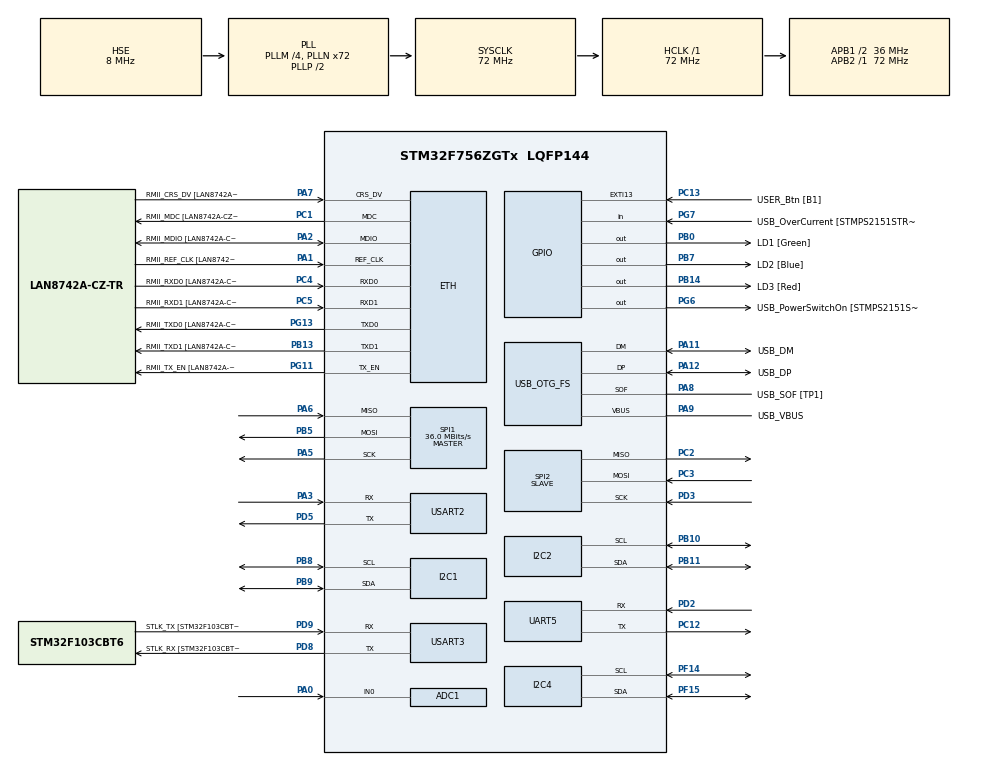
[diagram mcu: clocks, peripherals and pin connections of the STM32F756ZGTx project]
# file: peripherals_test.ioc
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ADC1.Channel-0\#ChannelRegularConversion=ADC_CHANNEL_0
ADC1.NbrOfConversionFlag=1
ADC1.Rank-0\#ChannelRegularConversion=1
ADC1.SamplingTime-0\#ChannelRegularConversion=ADC_SAMPLETIME_3CYCLES
ADC1.master=1
Dma.ADC1.8.Direction=DMA_PERIPH_TO_MEMORY
Dma.ADC1.8.FIFOMode=DMA_FIFOMODE_DISABLE
Dma.ADC1.8.Instance=DMA2_Stream4
Dma.ADC1.8.MemDataAlignment=DMA_MDATAALIGN_HALFWORD
Dma.ADC1.8.MemInc=DMA_MINC_ENABLE
Dma.ADC1.8.Mode=DMA_CIRCULAR
Dma.ADC1.8.PeriphDataAlignment=DMA_PDATAALIGN_HALFWORD
Dma.ADC1.8.PeriphInc=DMA_PINC_DISABLE
Dma.ADC1.8.Priority=DMA_PRIORITY_LOW
Dma.Request0=USART2_RX
Dma.Request1=USART2_TX
Dma.Request2=UART5_RX
Dma.Request3=UART5_TX
Dma.Request4=SPI1_RX
Dma.Request5=SPI1_TX
Dma.Request6=SPI2_RX
Dma.Request7=SPI2_TX
Dma.Request8=ADC1
Dma.SPI1_RX.4.Direction=DMA_PERIPH_TO_MEMORY
Dma.SPI1_RX.4.FIFOMode=DMA_FIFOMODE_ENABLE
Dma.SPI1_RX.4.FIFOThreshold=DMA_FIFO_THRESHOLD_FULL
Dma.SPI1_RX.4.Instance=DMA2_Stream0
Dma.SPI1_RX.4.MemBurst=DMA_MBURST_SINGLE
Dma.SPI1_RX.4.MemDataAlignment=DMA_MDATAALIGN_BYTE
Dma.SPI1_RX.4.MemInc=DMA_MINC_ENABLE
Dma.SPI1_RX.4.Mode=DMA_NORMAL
Dma.SPI1_RX.4.PeriphBurst=DMA_PBURST_SINGLE
Dma.SPI1_RX.4.PeriphDataAlignment=DMA_PDATAALIGN_BYTE
Dma.SPI1_RX.4.PeriphInc=DMA_PINC_DISABLE
Dma.SPI1_RX.4.Priority=DMA_PRIORITY_HIGH
Dma.SPI1_TX.5.Direction=DMA_MEMORY_TO_PERIPH
Dma.SPI1_TX.5.FIFOMode=DMA_FIFOMODE_ENABLE
Dma.SPI1_TX.5.FIFOThreshold=DMA_FIFO_THRESHOLD_FULL
Dma.SPI1_TX.5.Instance=DMA2_Stream3
Dma.SPI1_TX.5.MemBurst=DMA_MBURST_SINGLE
Dma.SPI1_TX.5.MemDataAlignment=DMA_MDATAALIGN_BYTE
Dma.SPI1_TX.5.MemInc=DMA_MINC_ENABLE
Dma.SPI1_TX.5.Mode=DMA_NORMAL
Dma.SPI1_TX.5.PeriphBurst=DMA_PBURST_SINGLE
Dma.SPI1_TX.5.PeriphDataAlignment=DMA_PDATAALIGN_BYTE
Dma.SPI1_TX.5.PeriphInc=DMA_PINC_DISABLE
Dma.SPI1_TX.5.Priority=DMA_PRIORITY_HIGH
Dma.SPI2_RX.6.Direction=DMA_PERIPH_TO_MEMORY
Dma.SPI2_RX.6.FIFOMode=DMA_FIFOMODE_ENABLE
Dma.SPI2_RX.6.FIFOThreshold=DMA_FIFO_THRESHOLD_FULL
Dma.SPI2_RX.6.Instance=DMA1_Stream3
Dma.SPI2_RX.6.MemBurst=DMA_MBURST_SINGLE
Dma.SPI2_RX.6.MemDataAlignment=DMA_MDATAALIGN_BYTE
Dma.SPI2_RX.6.MemInc=DMA_MINC_ENABLE
Dma.SPI2_RX.6.Mode=DMA_NORMAL
Dma.SPI2_RX.6.PeriphBurst=DMA_PBURST_SINGLE
Dma.SPI2_RX.6.PeriphDataAlignment=DMA_PDATAALIGN_BYTE
Dma.SPI2_RX.6.PeriphInc=DMA_PINC_DISABLE
Dma.SPI2_RX.6.Priority=DMA_PRIORITY_HIGH
Dma.SPI2_TX.7.Direction=DMA_MEMORY_TO_PERIPH
Dma.SPI2_TX.7.FIFOMode=DMA_FIFOMODE_ENABLE
Dma.SPI2_TX.7.FIFOThreshold=DMA_FIFO_THRESHOLD_FULL
Dma.SPI2_TX.7.Instance=DMA1_Stream4
Dma.SPI2_TX.7.MemBurst=DMA_MBURST_SINGLE
Dma.SPI2_TX.7.MemDataAlignment=DMA_MDATAALIGN_BYTE
Dma.SPI2_TX.7.MemInc=DMA_MINC_ENABLE
Dma.SPI2_TX.7.Mode=DMA_NORMAL
Dma.SPI2_TX.7.PeriphBurst=DMA_PBURST_SINGLE
Dma.SPI2_TX.7.PeriphDataAlignment=DMA_PDATAALIGN_BYTE
Dma.SPI2_TX.7.PeriphInc=DMA_PINC_DISABLE
Dma.SPI2_TX.7.Priority=DMA_PRIORITY_HIGH
Dma.UART5_RX.2.Direction=DMA_PERIPH_TO_MEMORY
Dma.UART5_RX.2.FIFOMode=DMA_FIFOMODE_DISABLE
Dma.UART5_RX.2.Instance=DMA1_Stream0
Dma.UART5_RX.2.MemDataAlignment=DMA_MDATAALIGN_BYTE
Dma.UART5_RX.2.MemInc=DMA_MINC_ENABLE
Dma.UART5_RX.2.Mode=DMA_NORMAL
Dma.UART5_RX.2.PeriphDataAlignment=DMA_PDATAALIGN_BYTE
Dma.UART5_RX.2.PeriphInc=DMA_PINC_DISABLE
Dma.UART5_RX.2.Priority=DMA_PRIORITY_LOW
Dma.UART5_TX.3.Direction=DMA_MEMORY_TO_PERIPH
Dma.UART5_TX.3.FIFOMode=DMA_FIFOMODE_DISABLE
Dma.UART5_TX.3.Instance=DMA1_Stream7
Dma.UART5_TX.3.MemDataAlignment=DMA_MDATAALIGN_BYTE
Dma.UART5_TX.3.MemInc=DMA_MINC_ENABLE
Dma.UART5_TX.3.Mode=DMA_NORMAL
Dma.UART5_TX.3.PeriphDataAlignment=DMA_PDATAALIGN_BYTE
Dma.UART5_TX.3.PeriphInc=DMA_PINC_DISABLE
Dma.UART5_TX.3.Priority=DMA_PRIORITY_LOW
Dma.USART2_RX.0.Direction=DMA_PERIPH_TO_MEMORY
Dma.USART2_RX.0.FIFOMode=DMA_FIFOMODE_DISABLE
Dma.USART2_RX.0.Instance=DMA1_Stream5
Dma.USART2_RX.0.MemDataAlignment=DMA_MDATAALIGN_BYTE
Dma.USART2_RX.0.MemInc=DMA_MINC_ENABLE
Dma.USART2_RX.0.Mode=DMA_NORMAL
Dma.USART2_RX.0.PeriphDataAlignment=DMA_PDATAALIGN_BYTE
Dma.USART2_RX.0.PeriphInc=DMA_PINC_DISABLE
Dma.USART2_RX.0.Priority=DMA_PRIORITY_LOW
Dma.USART2_TX.1.Direction=DMA_MEMORY_TO_PERIPH
Dma.USART2_TX.1.FIFOMode=DMA_FIFOMODE_DISABLE
Dma.USART2_TX.1.Instance=DMA1_Stream6
Dma.USART2_TX.1.MemDataAlignment=DMA_MDATAALIGN_BYTE
Dma.USART2_TX.1.MemInc=DMA_MINC_ENABLE
Dma.USART2_TX.1.Mode=DMA_NORMAL
Dma.USART2_TX.1.PeriphDataAlignment=DMA_PDATAALIGN_BYTE
Dma.USART2_TX.1.PeriphInc=DMA_PINC_DISABLE
Dma.USART2_TX.1.Priority=DMA_PRIORITY_LOW
ETH.MediaInterface=HAL_ETH_RMII_MODE
ETH.PHY_Name=LAN8742A_PHY_ADDRESS
ETH.PHY_Value=0
ETH.PhyAddress=0
I2C1.Timing=0x00808CD2
I2C2.Timing=0x00808CD2
I2C4.OwnAddress=0x02
I2C4.Timing=0x00808CD2
LWIP.BSP.number=1
LWIP.GATEWAY_ADDRESS=010.100.102.001
LWIP.IP_ADDRESS=010.100.102.100
LWIP.LWIP_DHCP=0
LWIP.LWIP_RAM_HEAP_POINTER=0x20048000
LWIP.NETMASK_ADDRESS=255.255.255.000
LWIP.Version=v2.1.2_Cube
LWIP0.BSP.STBoard=false
LWIP0.BSP.api=BSP_COMPONENT_DRIVER
LWIP0.BSP.component=LAN8742
LWIP0.BSP.instance=LAN8742
LWIP0.BSP.name=Driver_PHY
LWIP0.BSP.semaphore=S_LAN8742
LWIP0.BSP.solution=LAN8742
Mcu.Family=STM32F7
Mcu.Name=STM32F756ZGTx
Mcu.Package=LQFP144
NVIC.ADC_IRQn=true\:0\:0\:false\:false\:true\:true\:true\:true
NVIC.DMA1_Stream0_IRQn=true\:0\:0\:false\:false\:true\:false\:true\:true
NVIC.DMA1_Stream3_IRQn=true\:0\:0\:false\:false\:true\:false\:true\:true
NVIC.DMA1_Stream4_IRQn=true\:0\:0\:false\:false\:true\:false\:true\:true
NVIC.DMA1_Stream5_IRQn=true\:0\:0\:false\:false\:true\:false\:true\:true
NVIC.DMA1_Stream6_IRQn=true\:0\:0\:false\:false\:true\:false\:true\:true
NVIC.DMA1_Stream7_IRQn=true\:0\:0\:false\:false\:true\:false\:true\:true
NVIC.DMA2_Stream0_IRQn=true\:0\:0\:false\:false\:true\:false\:true\:true
NVIC.DMA2_Stream3_IRQn=true\:0\:0\:false\:false\:true\:false\:true\:true
NVIC.DMA2_Stream4_IRQn=true\:0\:0\:false\:false\:true\:false\:true\:true
NVIC.ETH_IRQn=true\:0\:0\:false\:false\:true\:true\:true\:true
NVIC.I2C2_EV_IRQn=true\:0\:0\:false\:false\:true\:true\:true\:true
NVIC.I2C4_EV_IRQn=true\:0\:0\:false\:false\:true\:true\:true\:true
NVIC.PriorityGroup=NVIC_PRIORITYGROUP_4
NVIC.SPI1_IRQn=true\:0\:0\:false\:false\:true\:true\:true\:true
NVIC.SPI2_IRQn=true\:0\:0\:false\:false\:true\:true\:true\:true
NVIC.TIM6_DAC_IRQn=true\:0\:0\:false\:false\:true\:true\:true\:true
NVIC.UART5_IRQn=true\:0\:0\:false\:false\:true\:true\:true\:true
NVIC.USART2_IRQn=true\:0\:0\:false\:false\:true\:true\:true\:true
PA0/WKUP.Signal=ADCx_IN0
PA1.GPIO_Label=RMII_REF_CLK [LAN8742A-CZ-TR_REFCLK0]
PA1.Mode=RMII
PA1.Signal=ETH_REF_CLK
PA10.GPIO_Label=USB_ID
PA10.Signal=USB_OTG_FS_ID
PA11.GPIO_Label=USB_DM
PA11.Mode=Device_Only
PA11.Signal=USB_OTG_FS_DM
PA12.GPIO_Label=USB_DP
PA12.Mode=Device_Only
PA12.Signal=USB_OTG_FS_DP
PA13.GPIO_Label=TMS
PA13.Mode=Serial_Wire
PA13.Signal=SYS_JTMS-SWDIO
PA14.GPIO_Label=TCK
PA14.Mode=Serial_Wire
PA14.Signal=SYS_JTCK-SWCLK
PA2.GPIO_Label=RMII_MDIO [LAN8742A-CZ-TR_MDIO]
PA2.Mode=RMII
PA2.Signal=ETH_MDIO
PA3.Mode=Asynchronous
PA3.Signal=USART2_RX
PA5.Mode=Full_Duplex_Master
PA5.Signal=SPI1_SCK
PA6.Mode=Full_Duplex_Master
PA6.Signal=SPI1_MISO
PA7.GPIO_Label=RMII_CRS_DV [LAN8742A-CZ-TR_CRS_DV]
PA7.Mode=RMII
PA7.Signal=ETH_CRS_DV
PA8.GPIO_Label=USB_SOF [TP1]
PA8.Mode=Activate_SOF_FS
PA8.Signal=USB_OTG_FS_SOF
PA9.GPIO_Label=USB_VBUS
PA9.Mode=Activate_VBUS
PA9.Signal=USB_OTG_FS_VBUS
PB0.GPIO_Label=LD1 [Green]
PB0.Signal=GPIO_Output
PB10.GPIO_Pu=GPIO_PULLUP
PB10.Mode=I2C
PB10.Signal=I2C2_SCL
PB11.GPIO_Pu=GPIO_PULLUP
PB11.Mode=I2C
PB11.Signal=I2C2_SDA
PB13.GPIO_Label=RMII_TXD1 [LAN8742A-CZ-TR_TXD1]
PB13.Mode=RMII
PB13.Signal=ETH_TXD1
PB14.GPIO_Label=LD3 [Red]
PB14.Signal=GPIO_Output
PB3.GPIO_Label=SW0
PB3.Signal=SYS_JTDO-SWO
PB5.Mode=Full_Duplex_Master
PB5.Signal=SPI1_MOSI
PB7.GPIO_Label=LD2 [Blue]
PB7.Signal=GPIO_Output
PB8.Mode=I2C
PB8.Signal=I2C1_SCL
PB9.Mode=I2C
PB9.Signal=I2C1_SDA
PC1.GPIO_Label=RMII_MDC [LAN8742A-CZ-TR_MDC]
PC1.Mode=RMII
PC1.Signal=ETH_MDC
PC12.Mode=Asynchronous
PC12.Signal=UART5_TX
PC13.GPIO_Label=USER_Btn [B1]
PC13.Signal=GPXTI13
PC14/OSC32_IN.Mode=LSE-External-Oscillator
PC14/OSC32_IN.Signal=RCC_OSC32_IN
PC15/OSC32_OUT.Mode=LSE-External-Oscillator
PC15/OSC32_OUT.Signal=RCC_OSC32_OUT
PC2.Mode=Full_Duplex_Slave
PC2.Signal=SPI2_MISO
PC3.Mode=Full_Duplex_Slave
PC3.Signal=SPI2_MOSI
PC4.GPIO_Label=RMII_RXD0 [LAN8742A-CZ-TR_RXD0]
PC4.Mode=RMII
PC4.Signal=ETH_RXD0
PC5.GPIO_Label=RMII_RXD1 [LAN8742A-CZ-TR_RXD1]
PC5.Mode=RMII
PC5.Signal=ETH_RXD1
PD2.Mode=Asynchronous
PD2.Signal=UART5_RX
PD3.Mode=Full_Duplex_Slave
PD3.Signal=SPI2_SCK
PD5.Mode=Asynchronous
PD5.Signal=USART2_TX
PD8.GPIO_Label=STLK_RX [STM32F103CBT6_PA3]
PD8.Mode=Asynchronous
PD8.Signal=USART3_TX
PD9.GPIO_Label=STLK_TX [STM32F103CBT6_PA2]
PD9.Mode=Asynchronous
PD9.Signal=USART3_RX
PF14.GPIO_Pu=GPIO_PULLUP
PF14.Mode=I2C
PF14.Signal=I2C4_SCL
PF15.GPIO_Pu=GPIO_PULLUP
PF15.Mode=I2C
PF15.Signal=I2C4_SDA
PG11.GPIO_Label=RMII_TX_EN [LAN8742A-CZ-TR_TXEN]
PG11.Mode=RMII
PG11.Signal=ETH_TX_EN
PG13.GPIO_Label=RMII_TXD0 [LAN8742A-CZ-TR_TXD0]
PG13.Mode=RMII
PG13.Signal=ETH_TXD0
PG6.GPIO_Label=USB_PowerSwitchOn [STMPS2151STR_EN]
PG6.Signal=GPIO_Output
PG7.GPIO_Label=USB_OverCurrent [STMPS2151STR_FAULT]
PG7.Signal=GPIO_Input
PH0/OSC_IN.GPIO_Label=MCO [STM32F103CBT6_PA8]
PH0/OSC_IN.Mode=HSE-External-Clock-Source
PH0/OSC_IN.Signal=RCC_OSC_IN
PH1/OSC_OUT.Mode=HSE-External-Clock-Source
PH1/OSC_OUT.Signal=RCC_OSC_OUT
ProjectManager.HeapSize=0x2048
ProjectManager.StackSize=0x4096
ProjectManager.TargetToolchain=STM32CubeIDE
RCC.48MHZClocksFreq_Value=24000000
RCC.AHBFreq_Value=72000000
RCC.APB1CLKDivider=RCC_HCLK_DIV2
RCC.APB1Freq_Value=36000000
RCC.APB1TimFreq_Value=72000000
RCC.APB2Freq_Value=72000000
RCC.APB2TimFreq_Value=72000000
RCC.CortexFreq_Value=72000000
RCC.HCLKFreq_Value=72000000
RCC.HSE_VALUE=8000000
RCC.HSI_VALUE=16000000
RCC.PLLM=4
RCC.PLLMUL=RCC_PLL_MUL9
RCC.PLLN=72
RCC.PLLQ=3
RCC.PRESCALERUSB=RCC_USBCLKSOURCE_PLL_DIV1_5
RCC.SYSCLKFreq_VALUE=72000000
RCC.SYSCLKSource=RCC_SYSCLKSOURCE_PLLCLK
RCC.SYSCLKSourceVirtual=RCC_SYSCLKSOURCE_PLLCLK
RCC.USBFreq_Value=48000000
RCC.VCOOutputFreq_Value=144000000
SH.ADCx_IN0.0=ADC1_IN0,IN0
SPI1.BaudRatePrescaler=SPI_BAUDRATEPRESCALER_2
SPI1.CalculateBaudRate=36.0 MBits/s
SPI1.DataSize=SPI_DATASIZE_8BIT
SPI1.Direction=SPI_DIRECTION_2LINES
SPI1.Mode=SPI_MODE_MASTER
SPI1.VirtualType=VM_MASTER
SPI2.DataSize=SPI_DATASIZE_8BIT
SPI2.Direction=SPI_DIRECTION_2LINES
SPI2.Mode=SPI_MODE_SLAVE
SPI2.VirtualType=VM_SLAVE
TIM6.Period=10000-1
TIM6.Prescaler=7200-1
USART2.VirtualMode-Asynchronous=VM_ASYNC
USART3.VirtualMode-Asynchronous=VM_ASYNC
USB_OTG_FS.VirtualMode=Device_Only
VP_LWIP_VS_Enabled.Mode=Enabled
VP_TIM6_VS_ClockSourceINT.Mode=Enable_Timer
board=NUCLEO-F756ZG

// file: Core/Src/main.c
/* USER CODE BEGIN Header */
/**
  ******************************************************************************
  * @file           : main.c
  * @brief          : Main program body
  ******************************************************************************
  * @attention
  *
  * Copyright (c) 2025 STMicroelectronics.
  * All rights reserved.
  *
  * This software is licensed under terms that can be found in the LICENSE file
  * in the root directory of this software component.
  * If no LICENSE file comes with this software, it is provided AS-IS.
  *
  ******************************************************************************
  */
/* USER CODE END Header */
#include "main.h"
#include "adc.h"
#include "dma.h"
#include "i2c.h"
#include "lwip.h"
#include "spi.h"
#include "tim.h"
#include "usart.h"
#include "usb_otg.h"
#include "gpio.h"

/* USER CODE BEGIN Includes */
#include "server.h"
#include "protocol.h"
#include "peripherals.h"
/* USER CODE END Includes */

void SystemClock_Config(void);

/* USER CODE BEGIN 0 */
extern struct netif gnetif;
/* USER CODE END 0 */

int main(void)
{

  /* MCU Configuration--------------------------------------------------------*/

  /* Reset of all peripherals, Initializes the Flash interface and the Systick. */
  HAL_Init();

  /* Configure the system clock */
  SystemClock_Config();

  /* Initialize all configured peripherals */
  MX_GPIO_Init();
  MX_DMA_Init();
  MX_I2C1_Init();
  MX_USART3_UART_Init();
  MX_USB_OTG_FS_PCD_Init();
  MX_LWIP_Init();
  MX_USART2_UART_Init();
  MX_UART5_Init();
  MX_SPI1_Init();
  MX_SPI2_Init();
  MX_I2C2_Init();
  MX_I2C4_Init();
  MX_ADC1_Init();
  MX_TIM6_Init();
  /* USER CODE BEGIN 2 */
  udp_server_init();
  /* USER CODE END 2 */

  /* Infinite loop */
  while (1)
  {

    /* USER CODE BEGIN 3 */
	  MX_LWIP_Process();
  }
  /* USER CODE END 3 */
}

void SystemClock_Config(void)
{
  RCC_OscInitTypeDef RCC_OscInitStruct = {0};
  RCC_ClkInitTypeDef RCC_ClkInitStruct = {0};

  /** Configure LSE Drive Capability
  */
  HAL_PWR_EnableBkUpAccess();

  /** Configure the main internal regulator output voltage
  */
  __HAL_RCC_PWR_CLK_ENABLE();
  __HAL_PWR_VOLTAGESCALING_CONFIG(PWR_REGULATOR_VOLTAGE_SCALE3);

  /** Initializes the RCC Oscillators according to the specified parameters
  * in the RCC_OscInitTypeDef structure.
  */
  RCC_OscInitStruct.OscillatorType = RCC_OSCILLATORTYPE_HSE;
  RCC_OscInitStruct.HSEState = RCC_HSE_BYPASS;
  RCC_OscInitStruct.PLL.PLLState = RCC_PLL_ON;
  RCC_OscInitStruct.PLL.PLLSource = RCC_PLLSOURCE_HSE;
  RCC_OscInitStruct.PLL.PLLM = 4;
  RCC_OscInitStruct.PLL.PLLN = 72;
  RCC_OscInitStruct.PLL.PLLP = RCC_PLLP_DIV2;
  RCC_OscInitStruct.PLL.PLLQ = 3;
  if (HAL_RCC_OscConfig(&RCC_OscInitStruct) != HAL_OK)
  {
    Error_Handler();
  }

  /** Initializes the CPU, AHB and APB buses clocks
  */
  RCC_ClkInitStruct.ClockType = RCC_CLOCKTYPE_HCLK|RCC_CLOCKTYPE_SYSCLK
                              |RCC_CLOCKTYPE_PCLK1|RCC_CLOCKTYPE_PCLK2;
  RCC_ClkInitStruct.SYSCLKSource = RCC_SYSCLKSOURCE_PLLCLK;
  RCC_ClkInitStruct.AHBCLKDivider = RCC_SYSCLK_DIV1;
  RCC_ClkInitStruct.APB1CLKDivider = RCC_HCLK_DIV2;
  RCC_ClkInitStruct.APB2CLKDivider = RCC_HCLK_DIV1;

  if (HAL_RCC_ClockConfig(&RCC_ClkInitStruct, FLASH_LATENCY_2) != HAL_OK)
  {
    Error_Handler();
  }
}

void Error_Handler(void)
{
  __disable_irq();
  while (1)
  {
  }
}
